# MSP430G2X21 register map
Vendor: msp430gen; File version: v0.4.0-16-g4f822b9
Registers are 8-bit, read-write, reset 0x0 unless marked. A register's access mark holds for its fields unless they carry their own. Offsets are from the block's base; [hi:lo] are bit positions; {n}, {i} and the like mark numbered series; 'fields as' and 'values as' point back to an identical list.

## USI
Base 0x00000078
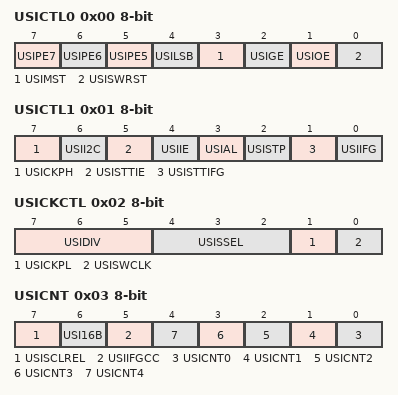
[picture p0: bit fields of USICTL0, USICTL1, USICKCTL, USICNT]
0x00 USICTL0 — USI Control Register 0
  [7] USIPE7 — USI Port Enable Px.7
  [6] USIPE6 — USI Port Enable Px.6
  [5] USIPE5 — USI Port Enable Px.5
  [4] USILSB — USI LSB first 1:LSB / 0:MSB
  [3] USIMST — USI Master Select 0:Slave / 1:Master
  [2] USIGE — USI General Output Enable Latch
  [1] USIOE — USI Output Enable
  [0] USISWRST — USI Software Reset
0x01 USICTL1 — USI Control Register 1
  [7] USICKPH — USI Sync. Mode: Clock Phase
  [6] USII2C — USI I2C Mode
  [5] USISTTIE — USI START Condition interrupt enable
  [4] USIIE — USI Counter Interrupt enable
  [3] USIAL — USI Arbitration Lost
  [2] USISTP — USI STOP Condition received
  [1] USISTTIFG — USI START Condition interrupt Flag
  [0] USIIFG — USI Counter Interrupt Flag
0x02 USICKCTL — USI Clock Control Register
  [7:5] USIDIV — USI Clock Divider 2
    {v}=USI Clock Divider: {v} (v=0..7)
  [4:2] USISSEL — USI Clock Source Select 2
    {v}=USI Clock Source: {v} (v=0..7)
  [1] USICKPL — USI Clock Polarity 0:Inactive=Low / 1:Inactive=High
  [0] USISWCLK — USI Software Clock
0x03 USICNT — USI Bit Counter Register
  [7] USISCLREL — USI SCL Released
  [6] USI16B — USI 16 Bit Shift Register Enable
  [5] USIIFGCC — USI Interrupt Flag Clear Control
  [n] USICNT{n} (n=0..4) — USI Bit Count {n}
0x04 USISRL — USI Low Byte Shift Register
0x05 USISRH — USI High Byte Shift Register

## CALIBRATION_DATA
Base 0x000010FE
0x00 CALDCO_1MHZ — DCOCTL Calibration Data for 1MHz
  [7:0] CALDCO_1MHZ — DCOCTL Calibration Data register
0x01 CALBC1_1MHZ — BCSCTL1 Calibration Data for 1MHz
  [7:0] CALBC1_1MHZ — BCSCTL1 Calibration Data register

## WATCHDOG_TIMER
Base 0x00000120
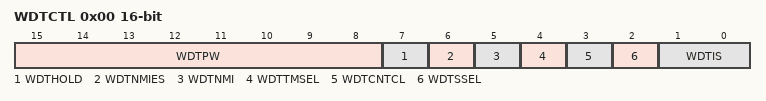
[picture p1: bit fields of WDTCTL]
0x00 WDTCTL 16-bit — Watchdog Timer Control
  [15:8] WDTPW — Watchdog Timer Password
    on read: 105=PASSWORD (Value always read from the Watchdog Password register) | on write: 90=PASSWORD (Value which must be written to the Watchdog Password register)
  [7] WDTHOLD
  [6] WDTNMIES
  [5] WDTNMI
  [4] WDTTMSEL
  [3] WDTCNTCL
  [2] WDTSSEL
  [1:0] WDTIS — WDTIS0

## FLASH
Base 0x00000128
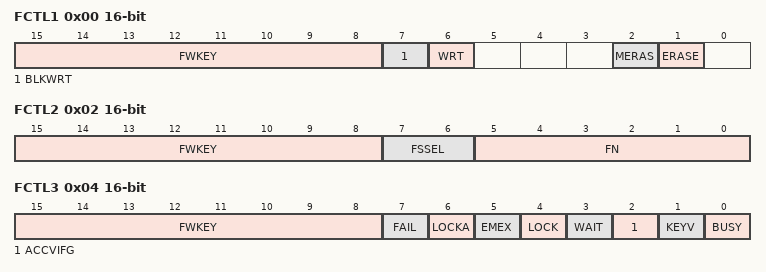
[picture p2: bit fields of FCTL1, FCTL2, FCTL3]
0x00 FCTL1 16-bit — FLASH Control 1
  [15:8] FWKEY — FCTL1 Password
    on read: 150=PASSWORD (Value always read from the FCTL1 Password register) | on write: 165=PASSWORD (Value which must be written to the FCTL1 Password register)
  [7] BLKWRT — Enable bit for Flash segment write
  [6] WRT — Enable bit for Flash write
  [2] MERAS — Enable bit for Flash mass erase
  [1] ERASE — Enable bit for Flash segment erase
0x02 FCTL2 16-bit — FLASH Control 2
  [15:8] FWKEY — FCTL2 Password
    on read: 150=PASSWORD (Value always read from the FCTL2 Password register) | on write: 165=PASSWORD (Value which must be written to the FCTL2 Password register)
  [7:6] FSSEL — Flash clock select 0 */ /* to distinguish from USART SSELx
    0=Flash clock select: 0 - ACLK; 1=Flash clock select: 1 - MCLK; 2=Flash clock select: 2 - SMCLK; 3=Flash clock select: 3 - SMCLK
  [5:0] FN — Divide Flash clock by 1 to 64 using FN0 to FN5 according to:
0x04 FCTL3 16-bit — FLASH Control 3
  [15:8] FWKEY — FCTL3 Password
    on read: 150=PASSWORD (Value always read from the FCTL3 Password register) | on write: 165=PASSWORD (Value which must be written to the FCTL3 Password register)
  [7] FAIL — Last Program or Erase failed
  [6] LOCKA — Segment A Lock bit: read = 1 - Segment is locked (read only)
  [5] EMEX — Flash Emergency Exit
  [4] LOCK — Lock bit: 1 - Flash is locked (read only)
  [3] WAIT — Wait flag for segment write
  [2] ACCVIFG — Flash Access violation flag
  [1] KEYV — Flash Key violation flag
  [0] BUSY — Flash busy: 1

## TIMER_A2
Base 0x0000012E
0x00 TAIV 16-bit — Timer A Interrupt Vector Word
  [3:0] TAIV — Timer A Interrupt Vector value
    0=NONE (No interrupt pending); 2=TACCR1 (Capture/Compare 1); 10=TAIFG (Timer overflow)
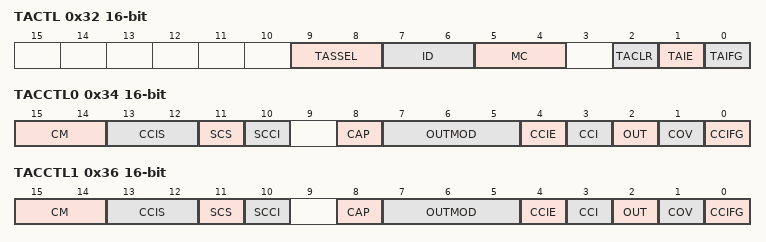
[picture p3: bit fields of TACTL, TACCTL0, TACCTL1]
0x32 TACTL 16-bit — Timer A Control
  [9:8] TASSEL — Timer A clock source select 1
    0=Timer A clock source select: 0 - TACLK; 1=Timer A clock source select: 1 - ACLK; 2=Timer A clock source select: 2 - SMCLK; 3=Timer A clock source select: 3 - INCLK
  [7:6] ID — Timer A clock input divider 1
    0=Timer A input divider: 0 - /1; 1=Timer A input divider: 1 - /2; 2=Timer A input divider: 2 - /4; 3=Timer A input divider: 3 - /8
  [5:4] MC — Timer A mode control 1
    0=Timer A mode control: 0 - Stop; 1=Timer A mode control: 1 - Up to CCR0; 2=Timer A mode control: 2 - Continous up; 3=Timer A mode control: 3 - Up/Down
  [2] TACLR — Timer A counter clear
  [1] TAIE — Timer A counter interrupt enable
  [0] TAIFG — Timer A counter interrupt flag
0x34 TACCTL0 16-bit — Timer A Capture/Compare Control 0
  [15:14] CM — Capture mode 1
    0=Capture mode: 0 - disabled; 1=Capture mode: 1 - pos. edge; 2=Capture mode: 1 - neg. edge; 3=Capture mode: 1 - both edges
  [13:12] CCIS — Capture input select 1
    0=Capture input select: 0 - CCIxA; 1=Capture input select: 1 - CCIxB; 2=Capture input select: 2 - GND; 3=Capture input select: 3 - Vcc
  [11] SCS — Capture sychronize
  [10] SCCI — Latched capture signal (read)
  [8] CAP — Capture mode: 1 /Compare mode : 0
  [7:5] OUTMOD — Output mode 2
    0=PWM output mode: 0 - output only; 1=PWM output mode: 1 - set; 2=PWM output mode: 2 - PWM toggle/reset; 3=PWM output mode: 3 - PWM set/reset; 4=PWM output mode: 4 - toggle; 5=PWM output mode: 5 - Reset; 6=PWM output mode: 6 - PWM toggle/set; 7=PWM output mode: 7 - PWM reset/set
  [4] CCIE — Capture/compare interrupt enable
  [3] CCI — Capture input signal (read)
  [2] OUT — PWM Output signal if output mode 0
  [1] COV — Capture/compare overflow flag
  [0] CCIFG — Capture/compare interrupt flag
0x36 TACCTL1 16-bit — Timer A Capture/Compare Control 1
  fields as TACCTL0
0x42 TAR 16-bit — Timer A Counter Register
0x44 TACCR0 16-bit — Timer A Capture/Compare 0
  [15:0] TACCR0 — Timer A Capture/Compare register 0
0x46 TACCR1 16-bit — Timer A Capture/Compare 1
  [15:0] TACCR1 — Timer A Capture/Compare register 1
